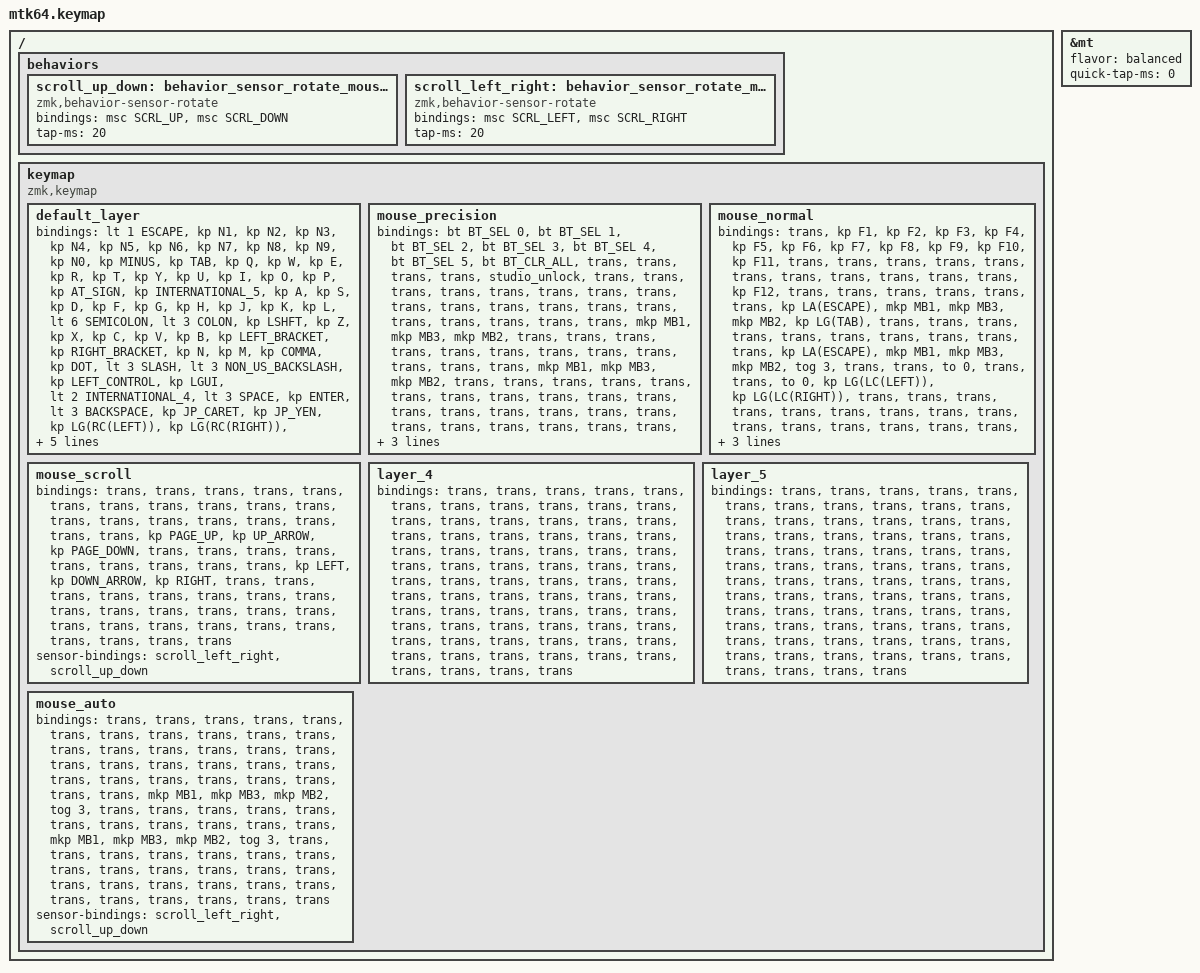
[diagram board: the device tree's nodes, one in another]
#include <behaviors.dtsi>
#include <dt-bindings/zmk/bt.h>
#include <dt-bindings/zmk/keys.h>
#include <dt-bindings/zmk/pointing.h>
#include "keycode_japanese.h"

// スクロール量の設定

#define ZMK_POINTING_DEFAULT_SCRL_VAL 100

&mt {
    flavor = "balanced";
    quick-tap-ms = <0>;
};

/ {
    behaviors {
        // 垂直スクロール用のbehaviorの設定

        scroll_up_down: behavior_sensor_rotate_mouse_wheel_up_down {
            compatible = "zmk,behavior-sensor-rotate";
            #sensor-binding-cells = <0>;
            bindings = <&msc SCRL_UP>, <&msc SCRL_DOWN>;

            tap-ms = <20>; // スクロールのタップ時間
        };

        // 水平スクロール用のbehaviorの設定

        scroll_left_right: behavior_sensor_rotate_mouse_wheel_left_right {
            compatible = "zmk,behavior-sensor-rotate";
            #sensor-binding-cells = <0>;
            bindings = <&msc SCRL_LEFT>, <&msc SCRL_RIGHT>;

            tap-ms = <20>; // スクロールのタップ時間
        };
    };
};

/ {
    keymap {
        compatible = "zmk,keymap";

        default_layer {
            bindings = <
&lt 1 ESCAPE  &kp N1  &kp N2  &kp N3  &kp N4  &kp N5  &kp N6  &kp N7  &kp N8  &kp N9  &kp N0  &kp MINUS  &kp TAB  &kp Q  &kp W  &kp E  &kp R  &kp T  &kp Y  &kp U  &kp I  &kp O  &kp P  &kp AT_SIGN  &kp INTERNATIONAL_5  &kp A  &kp S  &kp D  &kp F  &kp G  &kp H  &kp J  &kp K  &kp L  &lt 6 SEMICOLON  &lt 3 COLON  &kp LSHFT  &kp Z  &kp X  &kp C  &kp V  &kp B  &kp LEFT_BRACKET  &kp RIGHT_BRACKET  &kp N  &kp M  &kp COMMA  &kp DOT  &lt 3 SLASH  &lt 3 NON_US_BACKSLASH  &kp LEFT_CONTROL  &kp LGUI  &lt 2 INTERNATIONAL_4  &lt 3 SPACE  &kp ENTER  &lt 3 BACKSPACE  &kp JP_CARET  &kp JP_YEN  &kp LG(RC(LEFT))  &kp LG(RC(RIGHT))  &kp LEFT_ALT  &kp DEL  &none  &none  &mo 3  &tog 2  &mo 1  &mo 2  &mo 3  &mo 1  &mo 2  &mo 3  &mo 1  &mo 2  &mo 3
            >;

            sensor-bindings = <&scroll_left_right>, <&scroll_up_down>;
        };

        mouse_precision {
            bindings = <
&bt BT_SEL 0  &bt BT_SEL 1  &bt BT_SEL 2  &bt BT_SEL 3  &bt BT_SEL 4  &bt BT_SEL 5  &bt BT_CLR_ALL  &trans  &trans  &trans  &trans  &studio_unlock  &trans  &trans  &trans  &trans  &trans  &trans  &trans  &trans  &trans  &trans  &trans  &trans  &trans  &trans  &trans  &trans  &trans  &trans  &trans  &mkp MB1  &mkp MB3  &mkp MB2  &trans  &trans  &trans  &trans  &trans  &trans  &trans  &trans  &trans  &trans  &trans  &trans  &mkp MB1  &mkp MB3  &mkp MB2  &trans  &trans  &trans  &trans  &trans  &trans  &trans  &trans  &trans  &trans  &trans  &trans  &trans  &trans  &trans  &trans  &trans  &trans  &trans  &trans  &trans  &trans  &trans  &trans  &trans  &trans
            >;

            sensor-bindings = <&scroll_left_right>, <&scroll_up_down>;
        };

        mouse_normal {
            bindings = <
&trans  &kp F1  &kp F2  &kp F3  &kp F4  &kp F5  &kp F6  &kp F7  &kp F8  &kp F9  &kp F10  &kp F11  &trans  &trans  &trans  &trans  &trans  &trans  &trans  &trans  &trans  &trans  &trans  &kp F12  &trans  &trans  &trans  &trans  &trans  &trans  &kp LA(ESCAPE)  &mkp MB1  &mkp MB3  &mkp MB2  &kp LG(TAB)  &trans  &trans  &trans  &trans  &trans  &trans  &trans  &trans  &trans  &trans  &kp LA(ESCAPE)  &mkp MB1  &mkp MB3  &mkp MB2  &tog 3  &trans  &trans  &to 0  &trans  &trans  &to 0  &kp LG(LC(LEFT))  &kp LG(LC(RIGHT))  &trans  &trans  &trans  &trans  &trans  &trans  &trans  &trans  &trans  &trans  &trans  &trans  &trans  &trans  &trans  &trans  &trans
            >;

            sensor-bindings = <&scroll_left_right>, <&scroll_up_down>;
        };

        mouse_scroll {
            bindings = <
&trans  &trans  &trans  &trans  &trans  &trans  &trans  &trans  &trans  &trans  &trans  &trans  &trans  &trans  &trans  &trans  &trans  &trans  &trans  &kp PAGE_UP  &kp UP_ARROW  &kp PAGE_DOWN  &trans  &trans  &trans  &trans  &trans  &trans  &trans  &trans  &trans  &kp LEFT  &kp DOWN_ARROW  &kp RIGHT  &trans  &trans  &trans  &trans  &trans  &trans  &trans  &trans  &trans  &trans  &trans  &trans  &trans  &trans  &trans  &trans  &trans  &trans  &trans  &trans  &trans  &trans  &trans  &trans
            >;

            sensor-bindings = <
                &scroll_left_right
                &scroll_up_down
            >;
        };

        layer_4 {
            bindings = <
&trans  &trans  &trans  &trans  &trans  &trans  &trans  &trans  &trans  &trans  &trans  &trans  &trans  &trans  &trans  &trans  &trans  &trans  &trans  &trans  &trans  &trans  &trans  &trans  &trans  &trans  &trans  &trans  &trans  &trans  &trans  &trans  &trans  &trans  &trans  &trans  &trans  &trans  &trans  &trans  &trans  &trans  &trans  &trans  &trans  &trans  &trans  &trans  &trans  &trans  &trans  &trans  &trans  &trans  &trans  &trans  &trans  &trans  &trans  &trans  &trans  &trans  &trans  &trans  &trans  &trans  &trans  &trans  &trans  &trans  &trans  &trans  &trans  &trans  &trans
            >;
        };

        layer_5 {
            bindings = <
&trans  &trans  &trans  &trans  &trans  &trans  &trans  &trans  &trans  &trans  &trans  &trans  &trans  &trans  &trans  &trans  &trans  &trans  &trans  &trans  &trans  &trans  &trans  &trans  &trans  &trans  &trans  &trans  &trans  &trans  &trans  &trans  &trans  &trans  &trans  &trans  &trans  &trans  &trans  &trans  &trans  &trans  &trans  &trans  &trans  &trans  &trans  &trans  &trans  &trans  &trans  &trans  &trans  &trans  &trans  &trans  &trans  &trans  &trans  &trans  &trans  &trans  &trans  &trans  &trans  &trans  &trans  &trans  &trans  &trans  &trans  &trans  &trans  &trans  &trans
            >;
        };

        mouse_auto {
            bindings = <
&trans  &trans  &trans  &trans  &trans  &trans  &trans  &trans  &trans  &trans  &trans  &trans  &trans  &trans  &trans  &trans  &trans  &trans  &trans  &trans  &trans  &trans  &trans  &trans  &trans  &trans  &trans  &trans  &trans  &trans  &trans  &mkp MB1  &mkp MB3  &mkp MB2  &tog 3  &trans  &trans  &trans  &trans  &trans  &trans  &trans  &trans  &trans  &trans  &trans  &mkp MB1  &mkp MB3  &mkp MB2  &tog 3  &trans  &trans  &trans  &trans  &trans  &trans  &trans  &trans  &trans  &trans  &trans  &trans  &trans  &trans  &trans  &trans  &trans  &trans  &trans  &trans  &trans  &trans  &trans  &trans  &trans
            >;

            sensor-bindings = <&scroll_left_right>, <&scroll_up_down>;
        };
    };
};
